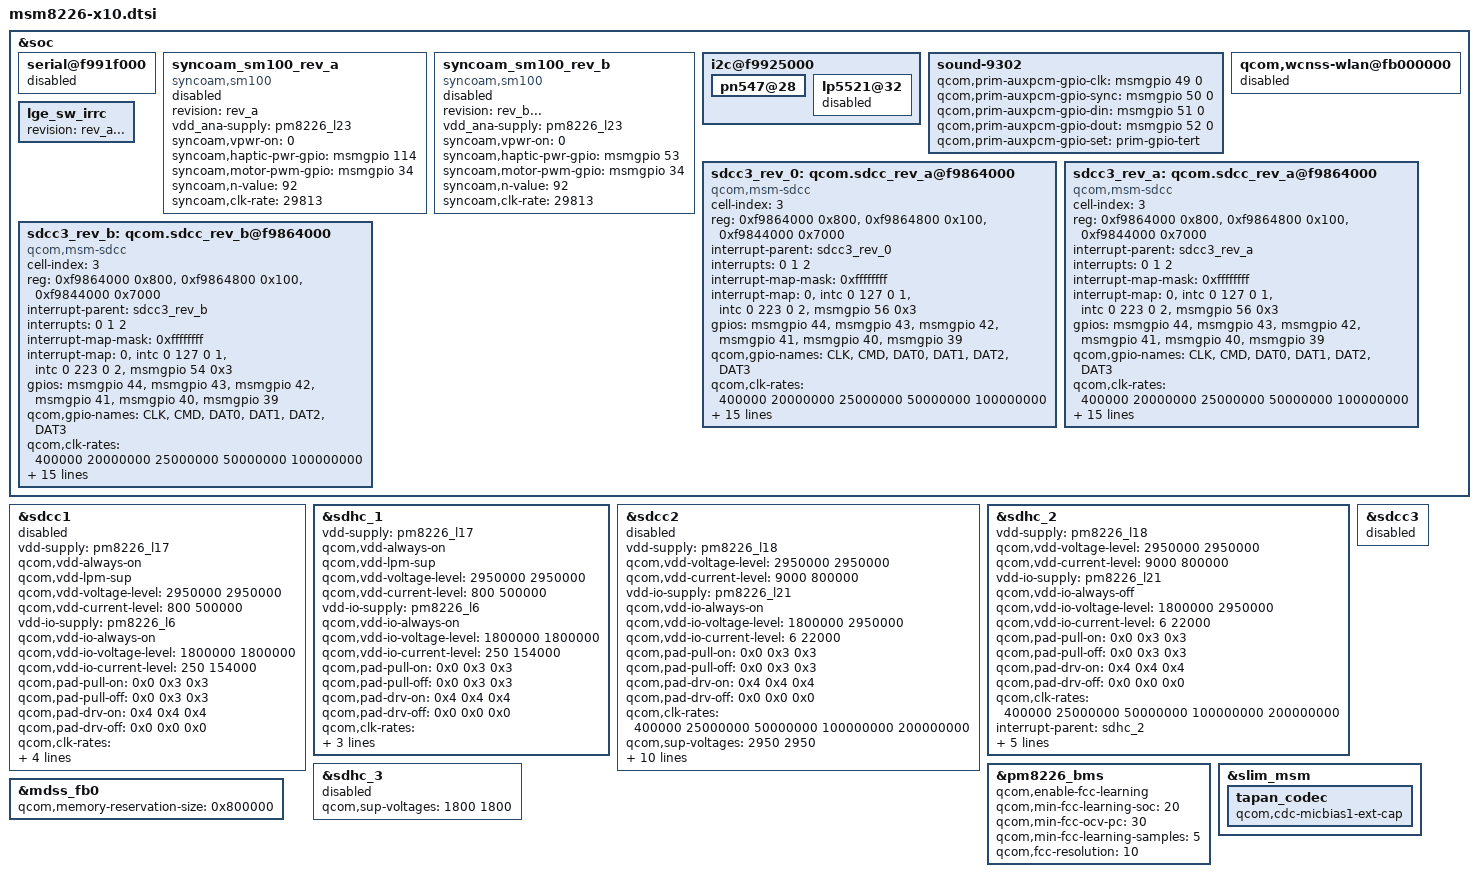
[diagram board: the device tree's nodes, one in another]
/* Copyright (c) 2012, Code Aurora Forum. All rights reserved.
 *
 * This program is free software; you can redistribute it and/or modify
 * it under the terms of the GNU General Public License version 2 and
 * only version 2 as published by the Free Software Foundation.
 *
 * This program is distributed in the hope that it will be useful,
 * but WITHOUT ANY WARRANTY; without even the implied warranty of
 * MERCHANTABILITY or FITNESS FOR A PARTICULAR PURPOSE.  See the
 * GNU General Public License for more details.
 */

/include/ "msm8226-x10-panel.dtsi"
/include/ "msm8226-x10-sensor.dtsi"
/include/ "msm8226-x10-hdmi.dtsi"
/include/ "msm8226-x10-usb.dtsi"
/include/ "msm8226-x10-misc.dtsi"
/include/ "msm8226-x10-pm.dtsi"
/include/ "msm8226-x10-camera.dtsi"
/include/ "msm8226-x10-input.dtsi"
/include/ "msm8226-x10-nfc.dtsi"  /* LGE_CHANGE, [NFC][garam.kim@lge.com], NFC Bring up */
/include/ "msm8226-x10-bt.dtsi" /* LGE_CHANGE, [BT] Bring up */

&soc {
	serial@f991f000 {
		status = "disable";
	};

	syncoam_sm100_rev_a {
		compatible = "syncoam,sm100";
		status = "disable";
		revision = "rev_a";
		
		vdd_ana-supply = <&pm8226_l23>;
		syncoam,vpwr-on = <0>;
		syncoam,haptic-pwr-gpio = <&msmgpio 114 0x00>;
		syncoam,motor-pwm-gpio = <&msmgpio 34 0x00>;
		syncoam,n-value = <92>;    //G2 final
		syncoam,clk-rate = <29813>;//G2 final
	};

	syncoam_sm100_rev_b {
		compatible = "syncoam,sm100";
		status = "disable";
		revision = "rev_b..."; // for CI(rev.e) SMT
		
		vdd_ana-supply = <&pm8226_l23>;
		syncoam,vpwr-on = <0>;
		syncoam,haptic-pwr-gpio = <&msmgpio 53 0x00>;
		syncoam,motor-pwm-gpio = <&msmgpio 34 0x00>;
		syncoam,n-value = <92>;    //G2 final
		syncoam,clk-rate = <29813>;//G2 final
	};	

	/*  LGE_CHANGE_S, [NFC][garam.kim@lge.com], NFC Bring up */
	i2c@f9925000 {
		pn547@28 {
			status = "ok";
		};
		lp5521@32 {
			status = "disable";
		};
	};
	/*  LGE_CHANGE_E, [NFC][garam.kim@lge.com], NFC Bring up */

	sound-9302 {
		qcom,prim-auxpcm-gpio-clk  = <&msmgpio 49 0>;
		qcom,prim-auxpcm-gpio-sync = <&msmgpio 50 0>;
		qcom,prim-auxpcm-gpio-din  = <&msmgpio 51 0>;
		qcom,prim-auxpcm-gpio-dout = <&msmgpio 52 0>;
		qcom,prim-auxpcm-gpio-set = "prim-gpio-tert";
	};
	/* wifi */
	qcom,wcnss-wlan@fb000000 {
		status = "disabled";
	};

	lge_sw_irrc { /* X10_IRRC */
        status = "ok";
        revision = "rev_a...";
        };
};

&soc {
	sdcc3_rev_0: qcom.sdcc_rev_a@f9864000 {
		cell-index = <3>;
		compatible = "qcom,msm-sdcc";
		reg = <0xf9864000 0x800>,
			<0xf9864800 0x100>,
			<0xf9844000 0x7000>;
		reg-names = "core_mem", "dml_mem", "bam_mem";
		#address-cells = <0>;
		interrupt-parent = <&sdcc3_rev_0>;
		interrupts = <0 1 2>;
		#interrupt-cells = <1>;
		interrupt-map-mask = <0xffffffff>;
		interrupt-map = <0 &intc 0 127 0
				1 &intc 0 223 0
				2 &msmgpio 56 0x3>;
		interrupt-names = "core_irq", "bam_irq", "wlan_oob_irq";

		gpios = <&msmgpio 44 0>, /* CLK */
			<&msmgpio 43 0>, /* CMD */
			<&msmgpio 42 0>, /* DATA0 */
			<&msmgpio 41 0>, /* DATA1 */
			<&msmgpio 40 0>, /* DATA2 */
			<&msmgpio 39 0>; /* DATA3 */
		qcom,gpio-names = "CLK", "CMD", "DAT0", "DAT1", "DAT2", "DAT3";
		qcom,clk-rates = <400000 20000000 25000000 50000000 100000000>;
                qcom,sup-voltages = <1800 2950>;
		qcom,bus-width = <4>;
		qcom,nonremovable;

		qcom,msm-bus,name = "sdcc3";
		qcom,msm-bus,num-cases = <8>;
		qcom,msm-bus,active-only = <0>;
		qcom,msm-bus,num-paths = <1>;
		qcom,msm-bus,vectors-KBps = <79 512 0 0>, /* No vote */
			<79 512 1600 3200>,    /* 400 KB/s*/
			<79 512 80000 160000>, /* 20 MB/s */
			<79 512 100000 200000>, /* 25 MB/s */
			<79 512 200000 400000>, /* 50 MB/s */
			<79 512 400000 800000>, /* 100 MB/s */
			<79 512 400000 800000>, /* 200 MB/s */
			<79 512 2048000 4096000>; /* Max. bandwidth */
		qcom,bus-bw-vectors-bps = <0 400000 20000000 25000000 50000000 100000000 200000000 4294967295>;
		revision = "rev_0";
		status = "ok";
	};

	sdcc3_rev_a: qcom.sdcc_rev_a@f9864000 {
		cell-index = <3>;
		compatible = "qcom,msm-sdcc";
		reg = <0xf9864000 0x800>,
			<0xf9864800 0x100>,
			<0xf9844000 0x7000>;
		reg-names = "core_mem", "dml_mem", "bam_mem";
		#address-cells = <0>;
		interrupt-parent = <&sdcc3_rev_a>;
		interrupts = <0 1 2>;
		#interrupt-cells = <1>;
		interrupt-map-mask = <0xffffffff>;
		interrupt-map = <0 &intc 0 127 0
				1 &intc 0 223 0
				2 &msmgpio 56 0x3>;
		interrupt-names = "core_irq", "bam_irq", "wlan_oob_irq";

		gpios = <&msmgpio 44 0>, /* CLK */
			<&msmgpio 43 0>, /* CMD */
			<&msmgpio 42 0>, /* DATA0 */
			<&msmgpio 41 0>, /* DATA1 */
			<&msmgpio 40 0>, /* DATA2 */
			<&msmgpio 39 0>; /* DATA3 */
		qcom,gpio-names = "CLK", "CMD", "DAT0", "DAT1", "DAT2", "DAT3";
		/*
		vdd-io-supply = <&pm8226_l12>;
		qcom,vdd-io-always-on;
		qcom,vdd-io-voltage-level = <1800000 1800000>;
		qcom,vdd-io-current-level = <250 154000>;

		vdd-supply = <&pm8226_l22>;
                qcom,vdd-voltage-level = <1800000 2950000>;
                qcom,vdd-current-level = <9000 800000>;
		*/
		qcom,clk-rates = <400000 20000000 25000000 50000000 100000000>;
		qcom,sup-voltages = <1800 2950>;
		qcom,bus-width = <4>;
		qcom,nonremovable;
		/*qcom,bus-speed-mode = "SDR12", "SDR25", "SDR50";*/

		qcom,msm-bus,name = "sdcc3";
		qcom,msm-bus,num-cases = <8>;
		qcom,msm-bus,active-only = <0>;
		qcom,msm-bus,num-paths = <1>;
		qcom,msm-bus,vectors-KBps = <79 512 0 0>, /* No vote */
			<79 512 1600 3200>,    /* 400 KB/s*/
			<79 512 80000 160000>, /* 20 MB/s */
			<79 512 100000 200000>, /* 25 MB/s */
			<79 512 200000 400000>, /* 50 MB/s */
			<79 512 400000 800000>, /* 100 MB/s */
			<79 512 400000 800000>, /* 200 MB/s */
			<79 512 2048000 4096000>; /* Max. bandwidth */
		qcom,bus-bw-vectors-bps = <0 400000 20000000 25000000 50000000 100000000 200000000 4294967295>;
		revision = "rev_a";
		status = "ok";
	};
        sdcc3_rev_b: qcom.sdcc_rev_b@f9864000 {
                cell-index = <3>;
                compatible = "qcom,msm-sdcc";
                reg = <0xf9864000 0x800>,
                        <0xf9864800 0x100>,
                        <0xf9844000 0x7000>;
                reg-names = "core_mem", "dml_mem", "bam_mem";
                #address-cells = <0>;
                interrupt-parent = <&sdcc3_rev_b>;
                interrupts = <0 1 2>;
                #interrupt-cells = <1>;
                interrupt-map-mask = <0xffffffff>;
                interrupt-map = <0 &intc 0 127 0
                                1 &intc 0 223 0
                                2 &msmgpio 54 0x3>;
                interrupt-names = "core_irq", "bam_irq", "wlan_oob_irq";

                gpios = <&msmgpio 44 0>, /* CLK */
                        <&msmgpio 43 0>, /* CMD */
                        <&msmgpio 42 0>, /* DATA0 */
                        <&msmgpio 41 0>, /* DATA1 */
                        <&msmgpio 40 0>, /* DATA2 */
                        <&msmgpio 39 0>; /* DATA3 */
                qcom,gpio-names = "CLK", "CMD", "DAT0", "DAT1", "DAT2", "DAT3";
                /*
                vdd-io-supply = <&pm8226_l12>;
                qcom,vdd-io-always-on;
                qcom,vdd-io-voltage-level = <1800000 1800000>;
                qcom,vdd-io-current-level = <250 154000>;

                vdd-supply = <&pm8226_l22>;
                qcom,vdd-voltage-level = <1800000 2950000>;
                qcom,vdd-current-level = <9000 800000>;
                */
                qcom,clk-rates = <400000 20000000 25000000 50000000 100000000>;
                //qcom,clk-rates = <400000 20000000 25000000 50000000>;
                qcom,sup-voltages = <1800 2950>;
                qcom,bus-width = <4>;
                qcom,nonremovable;
                /*qcom,bus-speed-mode = "SDR12", "SDR25", "SDR50";*/

                qcom,msm-bus,name = "sdcc3";
                qcom,msm-bus,num-cases = <8>;
                qcom,msm-bus,active-only = <0>;
                qcom,msm-bus,num-paths = <1>;
                qcom,msm-bus,vectors-KBps = <79 512 0 0>, /* No vote */
                        <79 512 1600 3200>,    /* 400 KB/s*/
                        <79 512 80000 160000>, /* 20 MB/s */
                        <79 512 100000 200000>, /* 25 MB/s */
                        <79 512 200000 400000>, /* 50 MB/s */
                        <79 512 400000 800000>, /* 100 MB/s */
                        <79 512 400000 800000>, /* 200 MB/s */
                        <79 512 2048000 4096000>; /* Max. bandwidth */
                qcom,bus-bw-vectors-bps = <0 400000 20000000 25000000 50000000 100000000 200000000 4294967295>;
                revision = "rev_b...";
                status = "ok";
        };


};


&sdcc1 {
	vdd-supply = <&pm8226_l17>;
	qcom,vdd-always-on;
	qcom,vdd-lpm-sup;
	qcom,vdd-voltage-level = <2950000 2950000>;
	qcom,vdd-current-level = <800 500000>;

	vdd-io-supply = <&pm8226_l6>;
	qcom,vdd-io-always-on;
	qcom,vdd-io-voltage-level = <1800000 1800000>;
	qcom,vdd-io-current-level = <250 154000>;

	qcom,pad-pull-on = <0x0 0x3 0x3>; /* no-pull, pull-up, pull-up */
	qcom,pad-pull-off = <0x0 0x3 0x3>; /* no-pull, pull-up, pull-up */
	qcom,pad-drv-on = <0x4 0x4 0x4>; /* 10mA, 10mA, 10mA */
	qcom,pad-drv-off = <0x0 0x0 0x0>; /* 2mA, 2mA, 2mA */

	qcom,clk-rates = <400000 25000000 50000000 100000000 200000000>;
	qcom,sup-voltages = <2950 2950>;

	qcom,bus-speed-mode = "HS200_1p8v", "DDR_1p8v";
	qcom,nonremovable;

   status = "disabled";
};

&sdhc_1 {
   vdd-supply = <&pm8226_l17>;
   qcom,vdd-always-on;
   qcom,vdd-lpm-sup;
   qcom,vdd-voltage-level = <2950000 2950000>;
   qcom,vdd-current-level = <800 500000>;

   vdd-io-supply = <&pm8226_l6>;
   qcom,vdd-io-always-on;
   qcom,vdd-io-voltage-level = <1800000 1800000>;
   qcom,vdd-io-current-level = <250 154000>;

   qcom,pad-pull-on = <0x0 0x3 0x3>; /* no-pull, pull-up, pull-up */
   qcom,pad-pull-off = <0x0 0x3 0x3>; /* no-pull, pull-up, pull-up */
   qcom,pad-drv-on = <0x4 0x4 0x4>; /* 10mA, 10mA, 10mA */
   qcom,pad-drv-off = <0x0 0x0 0x0>; /* 2mA, 2mA, 2mA */

   qcom,clk-rates = <400000 25000000 50000000 100000000 200000000>;
   qcom,bus-speed-mode = "HS200_1p8v", "DDR_1p8v";
   qcom,nonremovable;

	status = "ok";
};

&sdcc2 {
	vdd-supply = <&pm8226_l18>;
	qcom,vdd-voltage-level = <2950000 2950000>;
	qcom,vdd-current-level = <9000 800000>;

	vdd-io-supply = <&pm8226_l21>;
	qcom,vdd-io-always-on;
	qcom,vdd-io-voltage-level = <1800000 2950000>;
	qcom,vdd-io-current-level = <6 22000>;

	qcom,pad-pull-on = <0x0 0x3 0x3>; /* no-pull, pull-up, pull-up */
	qcom,pad-pull-off = <0x0 0x3 0x3>; /* no-pull, pull-up, pull-up */
	qcom,pad-drv-on = <0x4 0x4 0x4>; /* 10mA, 10mA, 10mA */
	qcom,pad-drv-off = <0x0 0x0 0x0>; /* 2mA, 2mA, 2mA */

	qcom,clk-rates = <400000 25000000 50000000 100000000 200000000>;
	qcom,sup-voltages = <2950 2950>;

	qcom,xpc;
	qcom,bus-speed-mode = "SDR12", "SDR25", "SDR50", "DDR50", "SDR104";
	qcom,current-limit = <600>; #address-cells = <0>; interrupt-parent = <&sdcc2>;
	interrupts = <0 1 2>;
	#interrupt-cells = <1>;
	interrupt-map-mask = <0xffffffff>;
	interrupt-map = <0 &intc 0 125 0
			1 &intc 0 220 0
			2 &msmgpio 38 0x3>;
	interrupt-names = "core_irq", "bam_irq", "status_irq";
	cd-gpios = <&msmgpio 38 0x0>; /* card detect 1:Low-Active, 0:High-Active */

   status = "disabled";
};

&sdhc_2 {
   vdd-supply = <&pm8226_l18>;
   qcom,vdd-voltage-level = <2950000 2950000>;
   qcom,vdd-current-level = <9000 800000>;

   vdd-io-supply = <&pm8226_l21>;
   qcom,vdd-io-always-off;
   qcom,vdd-io-voltage-level = <1800000 2950000>;
   qcom,vdd-io-current-level = <6 22000>;

   qcom,pad-pull-on = <0x0 0x3 0x3>; /* no-pull, pull-up, pull-up */
   qcom,pad-pull-off = <0x0 0x3 0x3>; /* no-pull, pull-up, pull-up */
   qcom,pad-drv-on = <0x4 0x4 0x4>; /* 10mA, 10mA, 10mA */
   qcom,pad-drv-off = <0x0 0x0 0x0>; /* 2mA, 2mA, 2mA */

   qcom,clk-rates = <400000 25000000 50000000 100000000 200000000>;

   #address-cells = <0>;
   interrupt-parent = <&sdhc_2>;
   interrupts = <0 1 2>;
   #interrupt-cells = <1>;
   interrupt-map-mask = <0xffffffff>;
   interrupt-map = <0 &intc 0 125 0
           1 &intc 0 221 0
           2 &msmgpio 37 0x3>;
   interrupt-names = "hc_irq", "pwr_irq", "status_irq";
   cd-gpios = <&msmgpio 37 0x1>; /* card detect 1:Low-Active, 0:High-Active  */

   status = "ok";
};
&sdcc3 {
    status = "disabled";
};

&sdhc_3 {
	qcom,sup-voltages = <1800 1800>;
	status = "disabled";
};

&pm8226_bms {
	status = "ok";
    qcom,enable-fcc-learning;
    qcom,min-fcc-learning-soc = <20>;
    qcom,min-fcc-ocv-pc = <30>;
    qcom,min-fcc-learning-samples = <5>;
    qcom,fcc-resolution = <10>;
};

&slim_msm {
    tapan_codec {
        qcom,cdc-micbias1-ext-cap;
    };
};
&mdss_fb0 {
	qcom,memory-reservation-size = <0x800000>;
};
